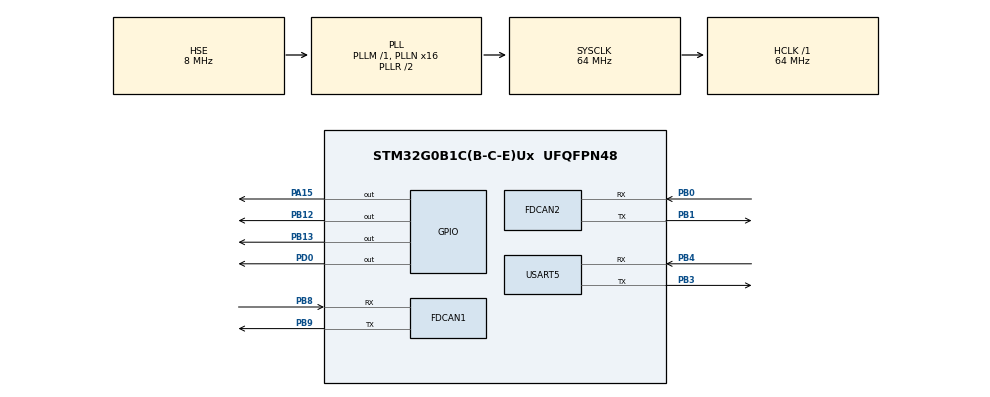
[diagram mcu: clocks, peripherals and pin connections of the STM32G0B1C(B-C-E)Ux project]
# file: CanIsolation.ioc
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Dma.Request0=USART5_RX
Dma.Request1=USART5_TX
Dma.USART5_RX.0.Direction=DMA_PERIPH_TO_MEMORY
Dma.USART5_RX.0.EventEnable=DISABLE
Dma.USART5_RX.0.Instance=DMA1_Channel1
Dma.USART5_RX.0.MemDataAlignment=DMA_MDATAALIGN_BYTE
Dma.USART5_RX.0.MemInc=DMA_MINC_ENABLE
Dma.USART5_RX.0.Mode=DMA_NORMAL
Dma.USART5_RX.0.PeriphDataAlignment=DMA_PDATAALIGN_BYTE
Dma.USART5_RX.0.PeriphInc=DMA_PINC_DISABLE
Dma.USART5_RX.0.Polarity=HAL_DMAMUX_REQ_GEN_RISING
Dma.USART5_RX.0.Priority=DMA_PRIORITY_LOW
Dma.USART5_RX.0.RequestNumber=1
Dma.USART5_RX.0.SignalID=NONE
Dma.USART5_RX.0.SyncEnable=DISABLE
Dma.USART5_RX.0.SyncPolarity=HAL_DMAMUX_SYNC_NO_EVENT
Dma.USART5_RX.0.SyncRequestNumber=1
Dma.USART5_RX.0.SyncSignalID=NONE
Dma.USART5_TX.1.Direction=DMA_MEMORY_TO_PERIPH
Dma.USART5_TX.1.EventEnable=DISABLE
Dma.USART5_TX.1.Instance=DMA1_Channel2
Dma.USART5_TX.1.MemDataAlignment=DMA_MDATAALIGN_BYTE
Dma.USART5_TX.1.MemInc=DMA_MINC_ENABLE
Dma.USART5_TX.1.Mode=DMA_NORMAL
Dma.USART5_TX.1.PeriphDataAlignment=DMA_PDATAALIGN_BYTE
Dma.USART5_TX.1.PeriphInc=DMA_PINC_DISABLE
Dma.USART5_TX.1.Polarity=HAL_DMAMUX_REQ_GEN_RISING
Dma.USART5_TX.1.Priority=DMA_PRIORITY_LOW
Dma.USART5_TX.1.RequestNumber=1
Dma.USART5_TX.1.SignalID=NONE
Dma.USART5_TX.1.SyncEnable=DISABLE
Dma.USART5_TX.1.SyncPolarity=HAL_DMAMUX_SYNC_NO_EVENT
Dma.USART5_TX.1.SyncRequestNumber=1
Dma.USART5_TX.1.SyncSignalID=NONE
FDCAN1.AutoRetransmission=ENABLE
FDCAN1.CalculateBaudRateNominal=1000000
FDCAN1.CalculateTimeBitNominal=1000
FDCAN1.CalculateTimeQuantumNominal=62.5
FDCAN1.NominalPrescaler=4
FDCAN1.NominalTimeSeg1=11
FDCAN1.NominalTimeSeg2=4
FDCAN1.StdFiltersNbr=1
FDCAN2.AutoRetransmission=ENABLE
FDCAN2.CalculateBaudRateNominal=1000000
FDCAN2.CalculateTimeBitNominal=1000
FDCAN2.CalculateTimeQuantumNominal=62.5
FDCAN2.NominalPrescaler=4
FDCAN2.NominalTimeSeg1=11
FDCAN2.NominalTimeSeg2=4
FDCAN2.StdFiltersNbr=1
Mcu.Family=STM32G0
Mcu.Name=STM32G0B1C(B-C-E)Ux
Mcu.Package=UFQFPN48
NVIC.DMA1_Channel1_IRQn=true\:0\:0\:false\:false\:true\:false\:true\:true
NVIC.DMA1_Channel2_3_IRQn=true\:0\:0\:false\:false\:true\:false\:true\:true
NVIC.TIM16_FDCAN_IT0_IRQn=true\:0\:0\:false\:false\:true\:true\:true\:true
NVIC.TIM17_FDCAN_IT1_IRQn=true\:0\:0\:false\:false\:true\:true\:true\:true
NVIC.USART3_4_5_6_LPUART1_IRQn=true\:0\:0\:false\:false\:true\:true\:true\:true
PA15.PinState=GPIO_PIN_SET
PA15.Signal=GPIO_Output
PB0.GPIO_Speed=GPIO_SPEED_FREQ_VERY_HIGH
PB0.Mode=FDCAN_Activate
PB0.Signal=FDCAN2_RX
PB1.GPIO_Speed=GPIO_SPEED_FREQ_VERY_HIGH
PB1.Mode=FDCAN_Activate
PB1.Signal=FDCAN2_TX
PB12.Signal=GPIO_Output
PB13.Signal=GPIO_Output
PB3.Mode=Asynchronous
PB3.Signal=USART5_TX
PB4.Mode=Asynchronous
PB4.PinState=GPIO_PIN_SET
PB4.Signal=USART5_RX
PB8.GPIO_FM8=__NULL
PB8.GPIO_Speed=GPIO_SPEED_FREQ_VERY_HIGH
PB8.Mode=FDCAN_Activate
PB8.Signal=FDCAN1_RX
PB9.GPIO_FM9=__NULL
PB9.GPIO_Speed=GPIO_SPEED_FREQ_VERY_HIGH
PB9.Mode=FDCAN_Activate
PB9.Signal=FDCAN1_TX
PD0.PinState=GPIO_PIN_SET
PD0.Signal=GPIO_Output
PF0-OSC_IN\ (PF0).Mode=HSE-External-Oscillator
PF0-OSC_IN\ (PF0).Signal=RCC_OSC_IN
PF1-OSC_OUT\ (PF1).Mode=HSE-External-Oscillator
PF1-OSC_OUT\ (PF1).Signal=RCC_OSC_OUT
ProjectManager.HeapSize=0x200
ProjectManager.StackSize=0x400
ProjectManager.TargetToolchain=CMake
RCC.ADCFreq_Value=64000000
RCC.AHBFreq_Value=64000000
RCC.CortexFreq_Value=64000000
RCC.EXTERNAL_CLOCK_VALUE=48000
RCC.HCLKFreq_Value=64000000
RCC.HSE_VALUE=8000000
RCC.HSI48_VALUE=48000000
RCC.HSI_VALUE=16000000
RCC.LSE_VALUE=32768
RCC.PLLN=16
RCC.PLLSourceVirtual=RCC_PLLSOURCE_HSE
RCC.SYSCLKFreq_VALUE=64000000
RCC.SYSCLKSource=RCC_SYSCLKSOURCE_PLLCLK
RCC.USBFreq_Value=48000000
RCC.VCOOutputFreq_Value=128000000
USART5.VirtualMode-Asynchronous=VM_ASYNC
VP_SYS_VS_DBSignals.Mode=DisableDeadBatterySignals
board=custom

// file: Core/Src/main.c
/* USER CODE BEGIN Header */
/**
  ******************************************************************************
  * @file           : main.c
  * @brief          : Main program body
  ******************************************************************************
  * @attention
  *
  * Copyright (c) 2026 STMicroelectronics.
  * All rights reserved.
  *
  * This software is licensed under terms that can be found in the LICENSE file
  * in the root directory of this software component.
  * If no LICENSE file comes with this software, it is provided AS-IS.
  *
  ******************************************************************************
  */
/* USER CODE END Header */
#include "main.h"
#include "comm_bsp.h"

FDCAN_HandleTypeDef hfdcan1;
FDCAN_HandleTypeDef hfdcan2;

UART_HandleTypeDef huart5;
DMA_HandleTypeDef hdma_usart5_rx;
DMA_HandleTypeDef hdma_usart5_tx;

void SystemClock_Config(void);
static void MX_GPIO_Init(void);
static void MX_DMA_Init(void);
static void MX_FDCAN1_Init(void);
static void MX_FDCAN2_Init(void);
static void MX_USART5_UART_Init(void);

int main(void)
{

  /* MCU Configuration--------------------------------------------------------*/

  /* Reset of all peripherals, Initializes the Flash interface and the Systick. */
  HAL_Init();

  /* Configure the system clock */
  SystemClock_Config();

  /* Initialize all configured peripherals */
  MX_GPIO_Init();
  MX_DMA_Init();
  MX_FDCAN1_Init();
  MX_FDCAN2_Init();
  MX_USART5_UART_Init();
  /* USER CODE BEGIN 2 */
  CommBsp_Init();
  /* USER CODE END 2 */

  /* Infinite loop */
  /* USER CODE BEGIN WHILE */
  uint32_t last_gpio_toggle = HAL_GetTick();
  while (1)
  {
    /* USER CODE END WHILE */

    /* USER CODE BEGIN 3 */
    uint32_t now = HAL_GetTick();
    CommBsp_Task(now);

    if ((uint32_t)(now - last_gpio_toggle) >= 500U)
    {
      last_gpio_toggle = now;
      HAL_GPIO_TogglePin(GPIOB, GPIO_PIN_12 | GPIO_PIN_13);
    }
  }
  /* USER CODE END 3 */
}

void SystemClock_Config(void)
{
  RCC_OscInitTypeDef RCC_OscInitStruct = {0};
  RCC_ClkInitTypeDef RCC_ClkInitStruct = {0};

  /** Configure the main internal regulator output voltage
  */
  HAL_PWREx_ControlVoltageScaling(PWR_REGULATOR_VOLTAGE_SCALE1);

  /** Initializes the RCC Oscillators according to the specified parameters
  * in the RCC_OscInitTypeDef structure.
  */
  RCC_OscInitStruct.OscillatorType = RCC_OSCILLATORTYPE_HSE;
  RCC_OscInitStruct.HSEState = RCC_HSE_ON;
  RCC_OscInitStruct.PLL.PLLState = RCC_PLL_ON;
  RCC_OscInitStruct.PLL.PLLSource = RCC_PLLSOURCE_HSE;
  RCC_OscInitStruct.PLL.PLLM = RCC_PLLM_DIV1;
  RCC_OscInitStruct.PLL.PLLN = 16;
  RCC_OscInitStruct.PLL.PLLP = RCC_PLLP_DIV2;
  RCC_OscInitStruct.PLL.PLLQ = RCC_PLLQ_DIV2;
  RCC_OscInitStruct.PLL.PLLR = RCC_PLLR_DIV2;
  if (HAL_RCC_OscConfig(&RCC_OscInitStruct) != HAL_OK)
  {
    Error_Handler();
  }

  /** Initializes the CPU, AHB and APB buses clocks
  */
  RCC_ClkInitStruct.ClockType = RCC_CLOCKTYPE_HCLK|RCC_CLOCKTYPE_SYSCLK
                              |RCC_CLOCKTYPE_PCLK1;
  RCC_ClkInitStruct.SYSCLKSource = RCC_SYSCLKSOURCE_PLLCLK;
  RCC_ClkInitStruct.AHBCLKDivider = RCC_SYSCLK_DIV1;
  RCC_ClkInitStruct.APB1CLKDivider = RCC_HCLK_DIV1;

  if (HAL_RCC_ClockConfig(&RCC_ClkInitStruct, FLASH_LATENCY_2) != HAL_OK)
  {
    Error_Handler();
  }
}

static void MX_FDCAN1_Init(void)
{

  hfdcan1.Instance = FDCAN1;
  hfdcan1.Init.ClockDivider = FDCAN_CLOCK_DIV1;
  hfdcan1.Init.FrameFormat = FDCAN_FRAME_CLASSIC;
  hfdcan1.Init.Mode = FDCAN_MODE_NORMAL;
  hfdcan1.Init.AutoRetransmission = ENABLE;
  hfdcan1.Init.TransmitPause = DISABLE;
  hfdcan1.Init.ProtocolException = DISABLE;
  hfdcan1.Init.NominalPrescaler = 4;
  hfdcan1.Init.NominalSyncJumpWidth = 1;
  hfdcan1.Init.NominalTimeSeg1 = 11;
  hfdcan1.Init.NominalTimeSeg2 = 4;
  hfdcan1.Init.DataPrescaler = 1;
  hfdcan1.Init.DataSyncJumpWidth = 1;
  hfdcan1.Init.DataTimeSeg1 = 1;
  hfdcan1.Init.DataTimeSeg2 = 1;
  hfdcan1.Init.StdFiltersNbr = 1;
  hfdcan1.Init.ExtFiltersNbr = 0;
  hfdcan1.Init.TxFifoQueueMode = FDCAN_TX_FIFO_OPERATION;
  if (HAL_FDCAN_Init(&hfdcan1) != HAL_OK)
  {
    Error_Handler();
  }

}

static void MX_FDCAN2_Init(void)
{

  hfdcan2.Instance = FDCAN2;
  hfdcan2.Init.ClockDivider = FDCAN_CLOCK_DIV1;
  hfdcan2.Init.FrameFormat = FDCAN_FRAME_CLASSIC;
  hfdcan2.Init.Mode = FDCAN_MODE_NORMAL;
  hfdcan2.Init.AutoRetransmission = ENABLE;
  hfdcan2.Init.TransmitPause = DISABLE;
  hfdcan2.Init.ProtocolException = DISABLE;
  hfdcan2.Init.NominalPrescaler = 4;
  hfdcan2.Init.NominalSyncJumpWidth = 1;
  hfdcan2.Init.NominalTimeSeg1 = 11;
  hfdcan2.Init.NominalTimeSeg2 = 4;
  hfdcan2.Init.DataPrescaler = 1;
  hfdcan2.Init.DataSyncJumpWidth = 1;
  hfdcan2.Init.DataTimeSeg1 = 1;
  hfdcan2.Init.DataTimeSeg2 = 1;
  hfdcan2.Init.StdFiltersNbr = 1;
  hfdcan2.Init.ExtFiltersNbr = 0;
  hfdcan2.Init.TxFifoQueueMode = FDCAN_TX_FIFO_OPERATION;
  if (HAL_FDCAN_Init(&hfdcan2) != HAL_OK)
  {
    Error_Handler();
  }

}

static void MX_USART5_UART_Init(void)
{

  huart5.Instance = USART5;
  huart5.Init.BaudRate = 115200;
  huart5.Init.WordLength = UART_WORDLENGTH_8B;
  huart5.Init.StopBits = UART_STOPBITS_1;
  huart5.Init.Parity = UART_PARITY_NONE;
  huart5.Init.Mode = UART_MODE_TX_RX;
  huart5.Init.HwFlowCtl = UART_HWCONTROL_NONE;
  huart5.Init.OverSampling = UART_OVERSAMPLING_16;
  huart5.Init.OneBitSampling = UART_ONE_BIT_SAMPLE_DISABLE;
  huart5.Init.ClockPrescaler = UART_PRESCALER_DIV1;
  huart5.AdvancedInit.AdvFeatureInit = UART_ADVFEATURE_NO_INIT;
  if (HAL_UART_Init(&huart5) != HAL_OK)
  {
    Error_Handler();
  }

}

static void MX_DMA_Init(void)
{

  /* DMA controller clock enable */
  __HAL_RCC_DMA1_CLK_ENABLE();

  /* DMA interrupt init */
  /* DMA1_Channel1_IRQn interrupt configuration */
  HAL_NVIC_SetPriority(DMA1_Channel1_IRQn, 0, 0);
  HAL_NVIC_EnableIRQ(DMA1_Channel1_IRQn);
  /* DMA1_Channel2_3_IRQn interrupt configuration */
  HAL_NVIC_SetPriority(DMA1_Channel2_3_IRQn, 0, 0);
  HAL_NVIC_EnableIRQ(DMA1_Channel2_3_IRQn);

}

static void MX_GPIO_Init(void)
{
  GPIO_InitTypeDef GPIO_InitStruct = {0};

  /* GPIO Ports Clock Enable */
  __HAL_RCC_GPIOF_CLK_ENABLE();
  __HAL_RCC_GPIOB_CLK_ENABLE();
  __HAL_RCC_GPIOA_CLK_ENABLE();
  __HAL_RCC_GPIOD_CLK_ENABLE();

  /*Configure GPIO pin Output Level */
  HAL_GPIO_WritePin(GPIOB, GPIO_PIN_12|GPIO_PIN_13, GPIO_PIN_RESET);

  /*Configure GPIO pin Output Level */
  HAL_GPIO_WritePin(GPIOA, GPIO_PIN_15, GPIO_PIN_SET);

  /*Configure GPIO pin Output Level */
  HAL_GPIO_WritePin(GPIOD, GPIO_PIN_0, GPIO_PIN_SET);

  /*Configure GPIO pins : PB12 PB13 */
  GPIO_InitStruct.Pin = GPIO_PIN_12|GPIO_PIN_13;
  GPIO_InitStruct.Mode = GPIO_MODE_OUTPUT_PP;
  GPIO_InitStruct.Pull = GPIO_NOPULL;
  GPIO_InitStruct.Speed = GPIO_SPEED_FREQ_LOW;
  HAL_GPIO_Init(GPIOB, &GPIO_InitStruct);

  /*Configure GPIO pin : PA15 */
  GPIO_InitStruct.Pin = GPIO_PIN_15;
  GPIO_InitStruct.Mode = GPIO_MODE_OUTPUT_PP;
  GPIO_InitStruct.Pull = GPIO_NOPULL;
  GPIO_InitStruct.Speed = GPIO_SPEED_FREQ_LOW;
  HAL_GPIO_Init(GPIOA, &GPIO_InitStruct);

  /*Configure GPIO pin : PD0 */
  GPIO_InitStruct.Pin = GPIO_PIN_0;
  GPIO_InitStruct.Mode = GPIO_MODE_OUTPUT_PP;
  GPIO_InitStruct.Pull = GPIO_NOPULL;
  GPIO_InitStruct.Speed = GPIO_SPEED_FREQ_LOW;
  HAL_GPIO_Init(GPIOD, &GPIO_InitStruct);

}

void Error_Handler(void)
{
  __disable_irq();
  while (1)
  {
  }
}
